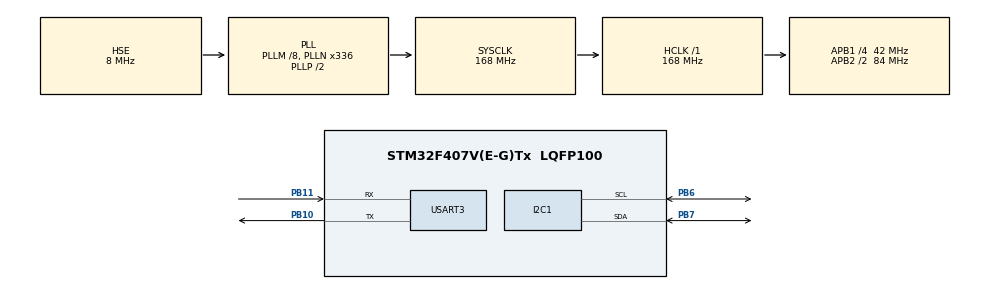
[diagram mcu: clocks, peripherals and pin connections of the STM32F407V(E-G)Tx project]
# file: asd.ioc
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Mcu.Family=STM32F4
Mcu.Name=STM32F407V(E-G)Tx
Mcu.Package=LQFP100
NVIC.PriorityGroup=NVIC_PRIORITYGROUP_0
NVIC.USART3_IRQn=true\:0\:0\:false\:false\:true\:true\:true
PB10.Mode=Asynchronous
PB10.Signal=USART3_TX
PB11.Mode=Asynchronous
PB11.Signal=USART3_RX
PB6.Mode=I2C
PB6.Signal=I2C1_SCL
PB7.Mode=I2C
PB7.Signal=I2C1_SDA
PH0-OSC_IN.Mode=HSE-External-Clock-Source
PH0-OSC_IN.Signal=RCC_OSC_IN
PH1-OSC_OUT.Mode=HSE-External-Clock-Source
PH1-OSC_OUT.Signal=RCC_OSC_OUT
ProjectManager.HeapSize=0x200
ProjectManager.StackSize=0x400
ProjectManager.TargetToolchain=STM32CubeIDE
RCC.48MHZClocksFreq_Value=48000000
RCC.AHBFreq_Value=168000000
RCC.APB1CLKDivider=RCC_HCLK_DIV4
RCC.APB1Freq_Value=42000000
RCC.APB1TimFreq_Value=84000000
RCC.APB2CLKDivider=RCC_HCLK_DIV2
RCC.APB2Freq_Value=84000000
RCC.APB2TimFreq_Value=168000000
RCC.CortexFreq_Value=168000000
RCC.HCLKFreq_Value=168000000
RCC.HSE_VALUE=8000000
RCC.HSI_VALUE=16000000
RCC.LSE_VALUE=32768
RCC.PLLM=8
RCC.PLLN=336
RCC.PLLQ=7
RCC.PLLSourceVirtual=RCC_PLLSOURCE_HSE
RCC.SYSCLKFreq_VALUE=168000000
RCC.SYSCLKSource=RCC_SYSCLKSOURCE_PLLCLK
RCC.VCOOutputFreq_Value=336000000
USART3.VirtualMode=VM_ASYNC
board=STM32F407G-DISC1

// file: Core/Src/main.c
/* USER CODE BEGIN Header */
/**
  ******************************************************************************
  * @file           : main.c
  * @brief          : Main program body
  ******************************************************************************
  * @attention
  *
  * <h2><center>&copy; Copyright (c) 2020 STMicroelectronics.
  * All rights reserved.</center></h2>
  *
  * This software component is licensed by ST under Ultimate Liberty license
  * SLA0044, the "License"; You may not use this file except in compliance with
  * the License. You may obtain a copy of the License at:
  *                             www.st.com/SLA0044
  *
  ******************************************************************************
  */
/* USER CODE END Header */

#include "main.h"

/* USER CODE BEGIN Includes */
#include "ESPDataLogger.h"
#include "sht21.h"
/* USER CODE END Includes */

I2C_HandleTypeDef hi2c1;

UART_HandleTypeDef huart3;

/* USER CODE BEGIN PV */
SHT21_Handle_t sht21_1 ;
/* USER CODE END PV */

void SystemClock_Config(void);
static void MX_GPIO_Init(void);
static void MX_USART3_UART_Init(void);
static void MX_I2C1_Init(void);

int main(void)
{

  /* MCU Configuration--------------------------------------------------------*/

  /* Reset of all peripherals, Initializes the Flash interface and the Systick. */
  HAL_Init();

  /* Configure the system clock */
  SystemClock_Config();

  /* Initialize all configured peripherals */
  MX_GPIO_Init();
  MX_USART3_UART_Init();
  MX_I2C1_Init();
  /* USER CODE BEGIN 2 */
  uint16_t Value_Buf[4];
  uint16_t i = 0 ;
  ESP_Init("MySSID", "123456789");
  /* USER CODE END 2 */

  /* Infinite loop */
  while (1)
  {

    /* USER CODE BEGIN 3 */
	  Temp_Measure(&sht21_1);
	  Hum_Measure(&sht21_1);

		Value_Buf[0] = sht21_1.son_sicaklik;
		Value_Buf[1] = sht21_1.son_nem;

		ESP_Send_Multi("4XM47IGFZHSTL3S6", 2, Value_Buf);
		HAL_Delay(10000);
		i++;
  }
  /* USER CODE END 3 */
}

void SystemClock_Config(void)
{
  RCC_OscInitTypeDef RCC_OscInitStruct = {0};
  RCC_ClkInitTypeDef RCC_ClkInitStruct = {0};

  /** Configure the main internal regulator output voltage
  */
  __HAL_RCC_PWR_CLK_ENABLE();
  __HAL_PWR_VOLTAGESCALING_CONFIG(PWR_REGULATOR_VOLTAGE_SCALE1);
  /** Initializes the CPU, AHB and APB busses clocks
  */
  RCC_OscInitStruct.OscillatorType = RCC_OSCILLATORTYPE_HSE;
  RCC_OscInitStruct.HSEState = RCC_HSE_BYPASS;
  RCC_OscInitStruct.PLL.PLLState = RCC_PLL_ON;
  RCC_OscInitStruct.PLL.PLLSource = RCC_PLLSOURCE_HSE;
  RCC_OscInitStruct.PLL.PLLM = 8;
  RCC_OscInitStruct.PLL.PLLN = 336;
  RCC_OscInitStruct.PLL.PLLP = RCC_PLLP_DIV2;
  RCC_OscInitStruct.PLL.PLLQ = 7;
  if (HAL_RCC_OscConfig(&RCC_OscInitStruct) != HAL_OK)
  {
    Error_Handler();
  }
  /** Initializes the CPU, AHB and APB busses clocks
  */
  RCC_ClkInitStruct.ClockType = RCC_CLOCKTYPE_HCLK|RCC_CLOCKTYPE_SYSCLK
                              |RCC_CLOCKTYPE_PCLK1|RCC_CLOCKTYPE_PCLK2;
  RCC_ClkInitStruct.SYSCLKSource = RCC_SYSCLKSOURCE_PLLCLK;
  RCC_ClkInitStruct.AHBCLKDivider = RCC_SYSCLK_DIV1;
  RCC_ClkInitStruct.APB1CLKDivider = RCC_HCLK_DIV4;
  RCC_ClkInitStruct.APB2CLKDivider = RCC_HCLK_DIV2;

  if (HAL_RCC_ClockConfig(&RCC_ClkInitStruct, FLASH_LATENCY_5) != HAL_OK)
  {
    Error_Handler();
  }
}

static void MX_I2C1_Init(void)
{

  hi2c1.Instance = I2C1;
  hi2c1.Init.ClockSpeed = 100000;
  hi2c1.Init.DutyCycle = I2C_DUTYCYCLE_2;
  hi2c1.Init.OwnAddress1 = 0;
  hi2c1.Init.AddressingMode = I2C_ADDRESSINGMODE_7BIT;
  hi2c1.Init.DualAddressMode = I2C_DUALADDRESS_DISABLE;
  hi2c1.Init.OwnAddress2 = 0;
  hi2c1.Init.GeneralCallMode = I2C_GENERALCALL_DISABLE;
  hi2c1.Init.NoStretchMode = I2C_NOSTRETCH_DISABLE;
  if (HAL_I2C_Init(&hi2c1) != HAL_OK)
  {
    Error_Handler();
  }

}

static void MX_USART3_UART_Init(void)
{

  huart3.Instance = USART3;
  huart3.Init.BaudRate = 115200;
  huart3.Init.WordLength = UART_WORDLENGTH_8B;
  huart3.Init.StopBits = UART_STOPBITS_1;
  huart3.Init.Parity = UART_PARITY_NONE;
  huart3.Init.Mode = UART_MODE_TX_RX;
  huart3.Init.HwFlowCtl = UART_HWCONTROL_NONE;
  huart3.Init.OverSampling = UART_OVERSAMPLING_16;
  if (HAL_UART_Init(&huart3) != HAL_OK)
  {
    Error_Handler();
  }

}

static void MX_GPIO_Init(void)
{

  /* GPIO Ports Clock Enable */
  __HAL_RCC_GPIOH_CLK_ENABLE();
  __HAL_RCC_GPIOB_CLK_ENABLE();

}

void Error_Handler(void)
{
}

/************************ (C) COPYRIGHT STMicroelectronics *****END OF FILE****/
